# GD32VF103 register map
File version: 1.0
CPU: RISC-V r1, little endian, MPU, FPU, 4 interrupt priority bits
Registers are read-write, reset 0x0 unless marked. A register's access mark holds for its fields unless they carry their own. Offsets are from the block's base; lines under a group give offsets from that group; [hi:lo] are bit positions; {n}, {i} and the like mark numbered series; 'fields as' and 'values as' point back to an identical list; <NAME> marks a mode.

## Memory map
0x40013800 USART0 size 0x400 — Universal synchronous asynchronous receiver transmitter

## USART0 — Universal synchronous asynchronous receiver transmitter
Base 0x40013800
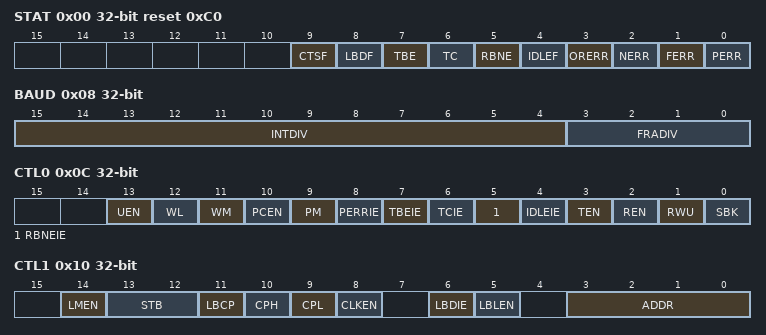
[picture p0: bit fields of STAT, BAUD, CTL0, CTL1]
0x00 STAT reset 0xC0 — Status register
  [9] CTSF — CTS change flag
  [8] LBDF — LIN break detection flag
  [7] TBE — Transmit data buffer empty
  [6] TC — Transmission complete
  [5] RBNE — Read data buffer not empty
  [4] IDLEF — IDLE line detected flag
  [3] ORERR — Overrun error flag
  [2] NERR — Noise error flag
  [1] FERR — Frame error flag
  [0] PERR — Parity error flag
0x04 DATA
  [8:0] DATA — Data value
0x08 BAUD — Baud rate register
  [15:4] INTDIV — Integer of baud-rate divider
  [3:0] FRADIV — Fraction of baud-rate divider
0x0C CTL0 — Control register 0
  [13] UEN — USART enable
  [12] WL — Word length
  [11] WM — Wakeup mode
  [10] PCEN — Parity check function enable
  [9] PM — Parity mode
  [8] PERRIE — Parity error interrupt enable
  [7] TBEIE — Transmitter buffer empty interrupt enable
  [6] TCIE — Transmission complete interrupt enable
  [5] RBNEIE — Read data buffer not empty interrupt enable
  [4] IDLEIE — IDLE line detected interrupt enable
  [3] TEN — Transmitter enable
  [2] REN — Receiver enable
  [1] RWU — Receiver wakeup from mute mode
  [0] SBK — Send break command
0x10 CTL1 — Control register 1
  [14] LMEN — LIN mode enable
  [13:12] STB — STOP bits
  [11] LBCP — Last bit clock pulse
  [10] CPH — Clock phase
  [9] CPL — Clock polarity
  [8] CLKEN — CK pin enable
  [6] LBDIE — LIN break detection interrupt enable
  [5] LBLEN — LIN break frame length
  [3:0] ADDR — Address of the USART terminal
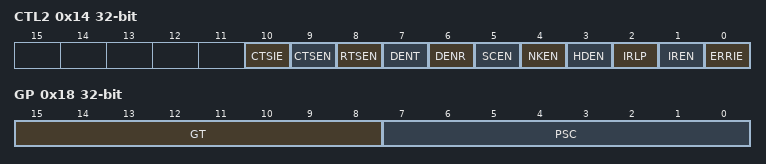
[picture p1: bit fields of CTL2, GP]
0x14 CTL2 — Control register 2
  [10] CTSIE — CTS interrupt enable
  [9] CTSEN — CTS enable
  [8] RTSEN — RTS enable
  [7] DENT — DMA request enable for transmission
  [6] DENR — DMA request enable for reception
  [5] SCEN — Smartcard mode enable
  [4] NKEN — Smartcard NACK enable
  [3] HDEN — Half-duplex selection
  [2] IRLP — IrDA low-power
  [1] IREN — IrDA mode enable
  [0] ERRIE — Error interrupt enable
0x18 GP — Guard time and prescaler register
  [15:8] GT — Guard time value
  [7:0] PSC — Prescaler value
